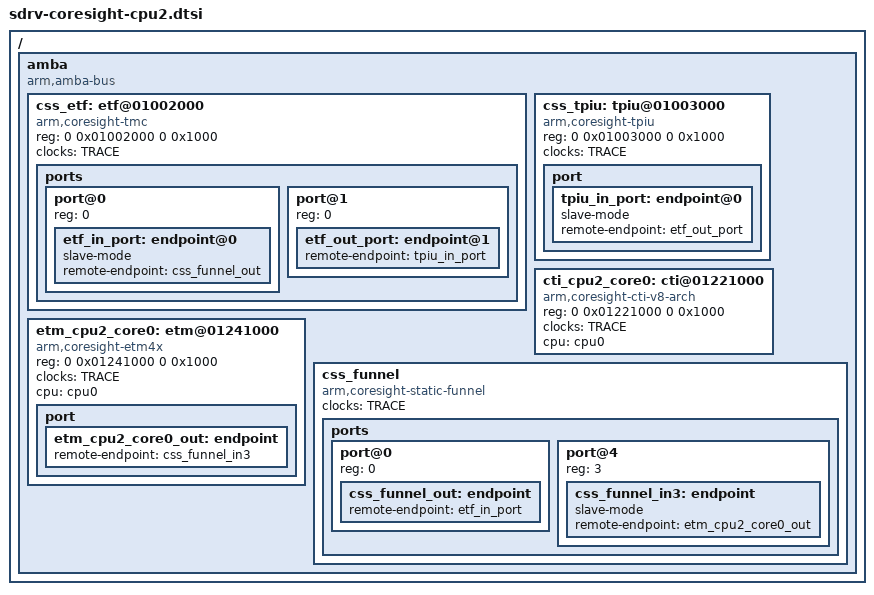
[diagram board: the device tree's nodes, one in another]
/*
 * Semidrive kunlun platform DTS file
 *
 * Copyright (C) 2019, Semidrive  Communications Inc.
 *
 * This file is licensed under a dual GPLv2 or X11 license.
 */

/ {
	amba {
		#address-cells = <2>;
		#size-cells = <2>;
		compatible = "arm,amba-bus";
		ranges;
		/* coresight 600 */
		css_etf: etf@01002000 {
			compatible = "arm,coresight-tmc", "arm,primecell";
			reg = <0 0x01002000 0 0x1000>;
			clocks = <&TRACE>;
			clock-names = "apb_pclk";
			ports {
				#address-cells = <1>;
				#size-cells = <0>;
				port@0 {
					reg = <0>;
					etf_in_port: endpoint@0 {
						slave-mode;
						remote-endpoint = <&css_funnel_out>;
					};
				};

				port@1 {
					reg = <0>;
					etf_out_port: endpoint@1 {
						remote-endpoint = <&tpiu_in_port>;
					};
				};
			};
		};

		css_tpiu: tpiu@01003000 {
			compatible = "arm,coresight-tpiu", "arm,primecell";
			reg = <0 0x01003000 0 0x1000>;
			clocks = <&TRACE>;
			clock-names = "apb_pclk";
			port {
				tpiu_in_port: endpoint@0 {
					slave-mode;
					remote-endpoint = <&etf_out_port>;
				};
			};
		};

		cti_cpu2_core0: cti@01221000 {
			compatible = "arm,coresight-cti-v8-arch", "arm,coresight-cti", "arm,primecell";
			reg = <0 0x01221000 0 0x1000>;
			clocks = <&TRACE>;
			clock-names = "apb_pclk";
			cpu = <&cpu0>;
		};

		etm_cpu2_core0: etm@01241000 {
			compatible = "arm,coresight-etm4x", "arm,primecell";
			reg = <0 0x01241000 0 0x1000>;
			clocks = <&TRACE>;
			clock-names = "apb_pclk";
			cpu = <&cpu0>;
			port {
				etm_cpu2_core0_out: endpoint {
					remote-endpoint = <&css_funnel_in3>;
				};
			};
		};

		css_funnel {
			/*
			 * non-configurable funnel don't show up on the AMBA
			 * bus.  As such no need to add "arm,primecell".
			*/
			compatible = "arm,coresight-static-funnel";
			clocks = <&TRACE>;
			clock-names = "apb_pclk";
			ports {
				#address-cells = <1>;
				#size-cells = <0>;
				/* funnel output port */
				port@0 {
					reg = <0>;
					css_funnel_out: endpoint {
						remote-endpoint = <&etf_in_port>;
					};
				};

				port@4 {
					reg = <3>;
					css_funnel_in3: endpoint {
						slave-mode;
						remote-endpoint = <&etm_cpu2_core0_out>;
					};
				};
			};
		};
	};
};
